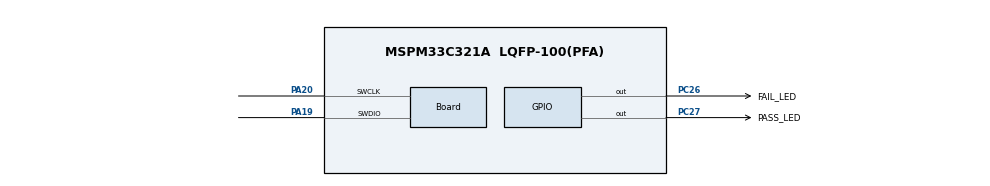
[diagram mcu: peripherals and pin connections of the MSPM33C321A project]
//@cliArgs --device "MSPM33C321A" --package "LQFP-100(PFA)" --part "Default"
//@v2CliArgs --device "MSPM33C321A" --package "LQFP-100(PFA)"
// @cliArgs --board /ti/boards/LP_MSPM33C321A --rtos nortos


/**
 * Import the modules used in this configuration.
 */
const GPIO   = scripting.addModule("/ti/driverlib/GPIO", {}, false);
const GPIO1  = GPIO.addInstance();
const SYSCTL = scripting.addModule("/ti/driverlib/SYSCTL");
const WWDT   = scripting.addModule("/ti/driverlib/WWDT", {}, false);
const WWDT1  = WWDT.addInstance();


/**
 * Write custom configuration values to the imported modules.
 */
GPIO1.$name                               = "GPIO_LEDS";
GPIO1.associatedPins.create(2);
GPIO1.associatedPins[0].$name             = "PASS_LED";
GPIO1.associatedPins[0].launchPadShortcut = "LED2GreenEn";
GPIO1.associatedPins[0].pin.$assign       = "PC27";
GPIO1.associatedPins[1].$name             = "FAIL_LED";
GPIO1.associatedPins[1].launchPadShortcut = "LED2RedEn";
GPIO1.associatedPins[1].pin.$assign       = "PC26";

const Board                       = scripting.addModule("/ti/driverlib/Board", {}, false);
Board.peripheral.$assign          = "DEBUGSS";
Board.peripheral.swclkPin.$assign = "PA20";
Board.peripheral.swdioPin.$assign = "PA19";

SYSCTL.powerPolicy        = "STANDBY0";
SYSCTL.peripheral.$assign = "SYSCTL";

WWDT1.$name              = "WWDT0";
WWDT1.wwdtMode           = "INTERVAL";
WWDT1.sleepMode          = true;
WWDT1.enabledInterrupts  = true;
WWDT1.peripheral.$assign = "WWDT0";

const ProjectConfig              = scripting.addModule("/ti/project_config/ProjectConfig", {}, false);
ProjectConfig.migrationCondition = true;

ProjectConfig.genLinker  = true;
ProjectConfig.genStartup = true;
ProjectConfig.genOpts    = true;
ProjectConfig.genLibs    = true;
